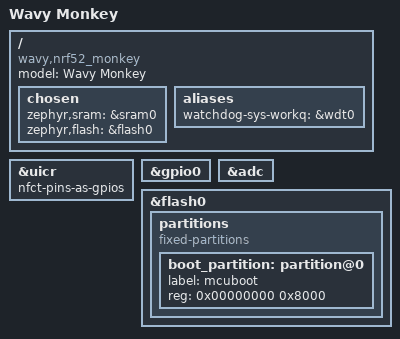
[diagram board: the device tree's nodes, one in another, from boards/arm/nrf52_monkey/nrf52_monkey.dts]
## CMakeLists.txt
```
cmake_minimum_required(VERSION 3.20.0)
find_package(Zephyr REQUIRED HINTS $ENV{ZEPHYR_BASE})

project(cap_touch)

include_directories(${CMAKE_SOURCE_DIR}/src)

target_sources(app PRIVATE src/main.c)

add_subdirectory(src/bluetooth)
add_subdirectory(src/io)
add_subdirectory(src/utils)
add_subdirectory(src/cap_touch)
```

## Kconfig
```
source "Kconfig.zephyr"

choice CAP_TOUCH_METHOD
    bool "Foo choice"
    default CAP_TOUCH_COMP_CURRENT

config CAP_TOUCH_COMP_CURRENT
    bool "A"

config CAP_TOUCH_COMP_RC
    bool "B"

config CAP_TOUCH_GPIO_RC
    bool "C"

config CAP_TOUCH_ADC_CHARGE_SHARE
    bool "D"
endchoice
```

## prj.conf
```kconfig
CONFIG_REBOOT=y
CONFIG_FPU=n
CONFIG_GPIO=y

# internal LF clock, much lower power consumption because HFCLK does not need to run
CONFIG_CLOCK_CONTROL_NRF_K32SRC_RC=y 

# Enable MPU
CONFIG_ARM_MPU=y

CONFIG_PINCTRL=y

# Enable hardware stack protection
CONFIG_HW_STACK_PROTECTION=y


CONFIG_CAP_TOUCH_COMP_CURRENT=y
# CONFIG_CAP_TOUCH_ADC_CHARGE_SHARE=y
```

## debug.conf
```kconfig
CONFIG_DEBUG=y

CONFIG_LOG=y
CONFIG_CONSOLE=y
# CONFIG_LOG_MODE_IMMEDIATE=y

# bluetooth logging
CONFIG_BT=y
CONFIG_BT_PERIPHERAL=y
CONFIG_BT_RX_STACK_SIZE=2048
CONFIG_BT_DEVICE_APPEARANCE=960
CONFIG_BT_CTLR_TX_PWR_MINUS_12=y

CONFIG_BT_DEVICE_NAME="CAPTOUCH"
```

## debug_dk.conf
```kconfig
CONFIG_DEBUG=y
CONFIG_LOG=y
CONFIG_CONSOLE=y
CONFIG_LOG_MODE_IMMEDIATE=n
```

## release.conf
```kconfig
CONFIG_DEBUG=n
CONFIG_CONSOLE=n
```

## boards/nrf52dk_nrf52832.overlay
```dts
/ {};

&adc {
	status = "okay";
};

// disable rest
&uart0 {
	status = "okay";
};

&i2c0 {
	status = "disabled";
};

&i2c1 {
	status = "disabled";
};

&pwm0 {
	status = "disabled";
};

&spi0 {
	status = "disabled";
};

&spi1 {
	status = "disabled";
};

&spi2 {
	status = "disabled";
};
```

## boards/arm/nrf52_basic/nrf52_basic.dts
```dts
/dts-v1/;
#include <nordic/nrf52832_qfaa.dtsi>
#include <zephyr/dt-bindings/gpio/gpio.h>

/ {
	model = "Basic board";
	compatible = "nrf52,basic";

	chosen {
		zephyr,sram = &sram0;
		zephyr,flash = &flash0;
	};
};

&gpio0 {
	status = "okay";
};

&adc {
	status = "okay";
};

// &flash0 {
// 	partitions {
// 		compatible = "fixed-partitions";
// 		#address-cells = <1>;
// 		#size-cells = <1>;

// 		boot_partition: partition@0 {
// 			label = "mcuboot";
// 			reg = <0x00000000 0x8000>;
// 		};
// 	};
// };
```

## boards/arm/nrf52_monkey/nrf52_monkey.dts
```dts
/dts-v1/;
#include <nordic/nrf52832_qfaa.dtsi>
#include <zephyr/dt-bindings/gpio/gpio.h>

/ {
	model = "Wavy Monkey";
	compatible = "wavy,nrf52_monkey";

	chosen {
		zephyr,sram = &sram0;
		zephyr,flash = &flash0;
	};

	aliases {
		watchdog-sys-workq = &wdt0;
	};
};

&uicr {
	nfct-pins-as-gpios;
};

&gpio0 {
	status = "okay";
};

&adc {
	status = "okay";
};

&flash0 {
	partitions {
		compatible = "fixed-partitions";
		#address-cells = <1>;
		#size-cells = <1>;

		boot_partition: partition@0 {
			label = "mcuboot";
			reg = <0x00000000 0x8000>;
		};
	};
};
```

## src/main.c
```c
/*
 * File: main.c
 * Author: Rein Gundersen Bentdal
 * Created: 19.Des 2024
 *
 * Copyright (c) 2024, Rein Gundersen Bentdal
 *
 * Permission is hereby granted, free of charge, to any person obtaining a copy
 * of this software and associated documentation files (the "Software"), to deal
 * in the Software without restriction, including without limitation the rights
 * to use, copy, modify, merge, publish, distribute, sublicense, and/or sell
 * copies of the Software, and to permit persons to whom the Software is
 * furnished to do so, subject to the following conditions:
 *
 * The above copyright notice and this permission notice shall be included in
 * all copies or substantial portions of the Software.
 *
 * THE SOFTWARE IS PROVIDED "AS IS", WITHOUT WARRANTY OF ANY KIND, EXPRESS OR
 * IMPLIED, INCLUDING BUT NOT LIMITED TO THE WARRANTIES OF MERCHANTABILITY,
 * FITNESS FOR A PARTICULAR PURPOSE AND NONINFRINGEMENT. IN NO EVENT SHALL THE
 * AUTHORS OR COPYRIGHT HOLDERS BE LIABLE FOR ANY CLAIM, DAMAGES OR OTHER
 * LIABILITY, WHETHER IN AN ACTION OF CONTRACT, TORT OR OTHERWISE, ARISING FROM,
 * OUT OF OR IN CONNECTION WITH THE SOFTWARE OR THE USE OR OTHER DEALINGS IN
 * THE SOFTWARE.
 */

#include <zephyr/kernel.h>

#include "hardware_spec.h"
#include "cap_touch/cap_touch.h"
#include "io/led.h"

#if CONFIG_DEBUG
#include "bluetooth/bt_connection_manager.h"
static void _bt_event(enum bt_connection_state);
#endif

#include <zephyr/logging/log.h>
LOG_MODULE_REGISTER(main, LOG_LEVEL_INF);

static void _cap_touch_event(uint8_t value);

int main(void) {
    /* simple blinking to indicate whether the system is working or not */
    led_init(LED_PIN, PORT_COMMON, LED_POLARITY);

#if CONFIG_DEBUG
    /* using Bluetooth to send captouch data */
    bt_connection_init(_bt_event);
#endif

    cap_touch_init(_cap_touch_event, CAPTOUCH_PSEL_COMP, CAPTOUCH_PSEL_PIN);

    cap_touch_start();
    led_blink();

    while(true) {
        LOG_INF("test\n");
        k_sleep(K_SECONDS(5));
        led_blink();
    }
    return 0;
}

#if CONFIG_DEBUG
static void _bt_event(enum bt_connection_state) {
    led_blink();
}
#endif

static void _cap_touch_event(uint8_t value) {
    led_blink();
}
```

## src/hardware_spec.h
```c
/*
 * File: hardware_spec.h
 * Author: Rein Gundersen Bentdal
 * Created: 19.Des 2024
 *
 * Copyright (c) 2024, Rein Gundersen Bentdal
 *
 * Permission is hereby granted, free of charge, to any person obtaining a copy
 * of this software and associated documentation files (the "Software"), to deal
 * in the Software without restriction, including without limitation the rights
 * to use, copy, modify, merge, publish, distribute, sublicense, and/or sell
 * copies of the Software, and to permit persons to whom the Software is
 * furnished to do so, subject to the following conditions:
 *
 * The above copyright notice and this permission notice shall be included in
 * all copies or substantial portions of the Software.
 *
 * THE SOFTWARE IS PROVIDED "AS IS", WITHOUT WARRANTY OF ANY KIND, EXPRESS OR
 * IMPLIED, INCLUDING BUT NOT LIMITED TO THE WARRANTIES OF MERCHANTABILITY,
 * FITNESS FOR A PARTICULAR PURPOSE AND NONINFRINGEMENT. IN NO EVENT SHALL THE
 * AUTHORS OR COPYRIGHT HOLDERS BE LIABLE FOR ANY CLAIM, DAMAGES OR OTHER
 * LIABILITY, WHETHER IN AN ACTION OF CONTRACT, TORT OR OTHERWISE, ARISING FROM,
 * OUT OF OR IN CONNECTION WITH THE SOFTWARE OR THE USE OR OTHER DEALINGS IN
 * THE SOFTWARE.
 */

#pragma once

#include <stdbool.h>
#include <stdint.h>
#include <nrf.h>

// in this sample, everything is assumed to be on a single common GPIO port
#define PORT_COMMON NRF_P0

// select which LED to use
#define LED_PIN 25
#define LED_POLARITY 1

// which pin the cap electride is connected to
#define CAPTOUCH_PSEL_COMP COMP_PSEL_PSEL_AnalogInput7
#define CAPTOUCH_PSEL_PIN 31
```
